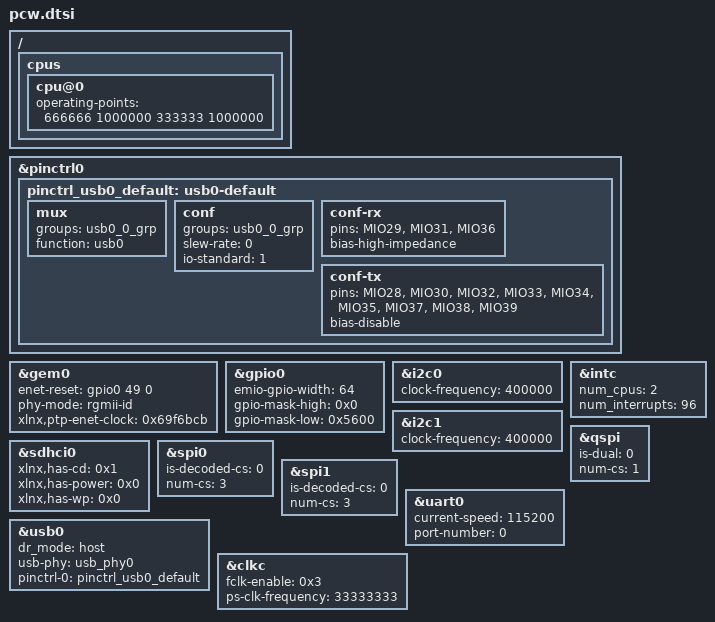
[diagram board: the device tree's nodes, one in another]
/*
 * CAUTION: This file is automatically generated by Xilinx.
 * Version: HSI 2015.4
 * Today is: Mon Jul  1 05:15:52 2019
*/


/ {
	cpus {
		cpu@0 {
			operating-points = <666666 1000000 333333 1000000>;
		};
	};
};
&pinctrl0 {
	pinctrl_usb0_default: usb0-default {
		mux {
			groups = "usb0_0_grp";
			function = "usb0";
		};

		conf {
			groups = "usb0_0_grp";
			slew-rate = <0>;
			io-standard = <1>;
		};

		conf-rx {
			pins = "MIO29", "MIO31", "MIO36";
			bias-high-impedance;
		};

		conf-tx {
			pins = "MIO28", "MIO30", "MIO32", "MIO33", "MIO34",
			       "MIO35", "MIO37", "MIO38", "MIO39";
			bias-disable;
		};
	};
};
&gem0 {
	enet-reset = <&gpio0 49 0>;
	phy-mode = "rgmii-id";
	status = "okay";
	xlnx,ptp-enet-clock = <0x69f6bcb>;
};
&gpio0 {
	emio-gpio-width = <64>;
	gpio-mask-high = <0x0>;
	gpio-mask-low = <0x5600>;
};
&i2c0 {
	clock-frequency = <400000>;
	status = "okay";
};
&i2c1 {
	clock-frequency = <400000>;
	status = "okay";
};
&intc {
	num_cpus = <2>;
	num_interrupts = <96>;
};
&qspi {
	is-dual = <0>;
	num-cs = <1>;
	status = "okay";
};
&sdhci0 {
	status = "okay";
	xlnx,has-cd = <0x1>;
	xlnx,has-power = <0x0>;
	xlnx,has-wp = <0x0>;
};
&spi0 {
	is-decoded-cs = <0>;
	num-cs = <3>;
	status = "okay";
};
&spi1 {
	is-decoded-cs = <0>;
	num-cs = <3>;
	status = "okay";
};
&uart0 {
	current-speed = <115200>;
	device_type = "serial";
	port-number = <0>;
	status = "okay";
};
&usb0 {
	status = "okay";
	dr_mode = "host";
	usb-phy = <&usb_phy0>;
	pinctrl-names = "default";
	pinctrl-0 = <&pinctrl_usb0_default>;
};
&clkc {
	fclk-enable = <0x3>;
	ps-clk-frequency = <33333333>;
};
